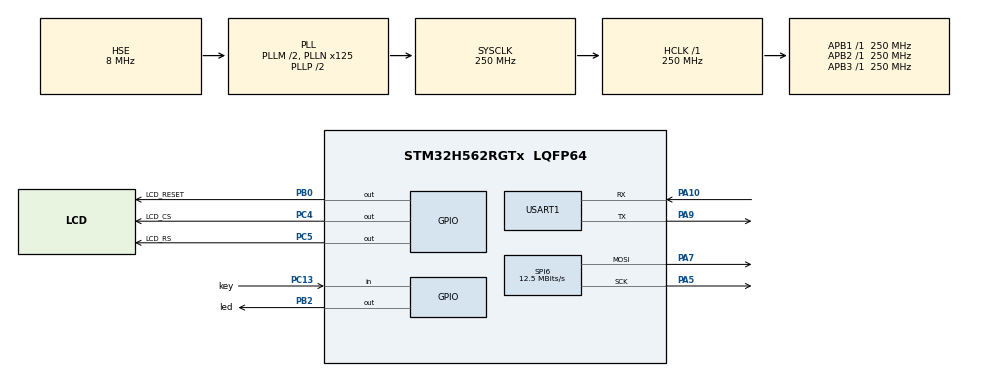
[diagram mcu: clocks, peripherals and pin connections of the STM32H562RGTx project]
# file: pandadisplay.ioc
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BOOTPATH.BootPathName=LEGACY
BOOTPATH.UserSelectedBootPath=LEGACY
CORTEX_M33_NS.userName=CORTEX_M33
Mcu.Family=STM32H5
Mcu.Name=STM32H562RGTx
Mcu.Package=LQFP64
NVIC.PriorityGroup=NVIC_PRIORITYGROUP_4
PA10.Mode=Asynchronous
PA10.Signal=USART1_RX
PA13(JTMS/SWDIO).Mode=Serial_Wire
PA13(JTMS/SWDIO).Signal=DEBUG_JTMS-SWDIO
PA14(JTCK/SWCLK).Mode=Serial_Wire
PA14(JTCK/SWCLK).Signal=DEBUG_JTCK-SWCLK
PA5.Mode=TX_Only_Simplex_Unidirect_Master
PA5.Signal=SPI6_SCK
PA7.Mode=TX_Only_Simplex_Unidirect_Master
PA7.Signal=SPI6_MOSI
PA9.Mode=Asynchronous
PA9.Signal=USART1_TX
PB0.GPIO_Label=LCD_RESET
PB0.PinState=GPIO_PIN_SET
PB0.Signal=GPIO_Output
PB2.GPIO_Label=led
PB2.Signal=GPIO_Output
PC13.GPIO_Label=key
PC13.Signal=GPIO_Input
PC4.GPIO_Label=LCD_CS
PC4.PinState=GPIO_PIN_SET
PC4.Signal=GPIO_Output
PC5.GPIO_Label=LCD_RS
PC5.Signal=GPIO_Output
PH0-OSC_IN(PH0).Mode=HSE-External-Oscillator
PH0-OSC_IN(PH0).Signal=RCC_OSC_IN
PH1-OSC_OUT(PH1).Mode=HSE-External-Oscillator
PH1-OSC_OUT(PH1).Signal=RCC_OSC_OUT
ProjectManager.HeapSize=0x200
ProjectManager.StackSize=0x400
ProjectManager.TargetToolchain=STM32CubeIDE
RCC.ADCFreq_Value=250000000
RCC.AHBFreq_Value=250000000
RCC.APB1Freq_Value=250000000
RCC.APB1TimFreq_Value=250000000
RCC.APB2Freq_Value=250000000
RCC.APB2TimFreq_Value=250000000
RCC.APB3Freq_Value=250000000
RCC.CSI_VALUE=4000000
RCC.CortexFreq_Value=250000000
RCC.EPOD_VALUE=8000000
RCC.HCLKFreq_Value=250000000
RCC.HSE_VALUE=8000000
RCC.HSI48_VALUE=48000000
RCC.HSI_VALUE=64000000
RCC.LSE_VALUE=32768
RCC.LSIRC_VALUE=32000
RCC.PLL2M=2
RCC.PLL2N=125
RCC.PLL2Q=10
RCC.PLL2Source=RCC_PLL2_SOURCE_HSE
RCC.PLLM=2
RCC.PLLN=125
RCC.PLLSourceVirtual=RCC_PLL1_SOURCE_HSE
RCC.SPI6CLockSelection=RCC_SPI6CLKSOURCE_PLL2Q
RCC.SYSCLKFreq_VALUE=250000000
RCC.SYSCLKSource=RCC_SYSCLKSOURCE_PLLCLK
RCC.USBFreq_Value=48000000
RCC.VCOOutputFreq_Value=500000000
SPI6.BaudRatePrescaler=SPI_BAUDRATEPRESCALER_4
SPI6.CLKPhase=SPI_PHASE_1EDGE
SPI6.CLKPolarity=SPI_POLARITY_LOW
SPI6.CalculateBaudRate=12.5 MBits/s
SPI6.DataSize=SPI_DATASIZE_8BIT
SPI6.Direction=SPI_DIRECTION_2LINES_TXONLY
SPI6.IOSwap=SPI_IO_SWAP_DISABLE
SPI6.Mode=SPI_MODE_MASTER
SPI6.VirtualType=VM_MASTER
USART1.VirtualMode-Asynchronous=VM_ASYNC
VP_BOOTPATH_VS_BOOTPATH.Mode=BP_Activate
VP_CORTEX_M33_NS_VS_Hclk.Mode=Hclk_Mode
VP_DCACHE1_VS_DCACHE.Mode=DCACHE_Activate
VP_ICACHE_VS_ICACHE.Mode=DefaultMode
VP_MEMORYMAP_VS_MEMORYMAP.Mode=CurAppReg
VP_PWR_VS_LPOM.Mode=PowerOptimisation
VP_PWR_VS_SECSignals.Mode=Security/Privilege
board=custom

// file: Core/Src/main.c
/* USER CODE BEGIN Header */
/**
  ******************************************************************************
  * @file           : main.c
  * @brief          : Main program body
  ******************************************************************************
  * @attention
  *
  * Copyright (c) 2025 STMicroelectronics.
  * All rights reserved.
  *
  * This software is licensed under terms that can be found in the LICENSE file
  * in the root directory of this software component.
  * If no LICENSE file comes with this software, it is provided AS-IS.
  *
  ******************************************************************************
  */
/* USER CODE END Header */
#include "main.h"

/* USER CODE BEGIN Includes */
#include "st75256.h"
/* USER CODE END Includes */

DCACHE_HandleTypeDef hdcache1;

SPI_HandleTypeDef hspi6;

UART_HandleTypeDef huart1;

void SystemClock_Config(void);
static void MX_GPIO_Init(void);
static void MX_ICACHE_Init(void);
static void MX_USART1_UART_Init(void);
static void MX_DCACHE1_Init(void);
static void MX_SPI6_Init(void);

int main(void)
{

  /* MCU Configuration--------------------------------------------------------*/

  /* Reset of all peripherals, Initializes the Flash interface and the Systick. */
  HAL_Init();

  /* Configure the system clock */
  SystemClock_Config();

  /* Initialize all configured peripherals */
  MX_GPIO_Init();
  MX_ICACHE_Init();
  MX_USART1_UART_Init();
  MX_DCACHE1_Init();
  MX_SPI6_Init();
  /* USER CODE BEGIN 2 */
  lcd_init();

  /* USER CODE END 2 */

  /* Infinite loop */
  /* USER CODE BEGIN WHILE */
  while (1)
  {
	  HAL_GPIO_TogglePin(led_GPIO_Port,led_Pin);

	  HAL_Delay(1000);

	  lcd_active250();
    /* USER CODE END WHILE */

  }
}

void SystemClock_Config(void)
{
  RCC_OscInitTypeDef RCC_OscInitStruct = {0};
  RCC_ClkInitTypeDef RCC_ClkInitStruct = {0};

  /** Configure the main internal regulator output voltage
  */
  __HAL_PWR_VOLTAGESCALING_CONFIG(PWR_REGULATOR_VOLTAGE_SCALE0);

  while(!__HAL_PWR_GET_FLAG(PWR_FLAG_VOSRDY)) {}

  /** Initializes the RCC Oscillators according to the specified parameters
  * in the RCC_OscInitTypeDef structure.
  */
  RCC_OscInitStruct.OscillatorType = RCC_OSCILLATORTYPE_HSE;
  RCC_OscInitStruct.HSEState = RCC_HSE_ON;
  RCC_OscInitStruct.PLL.PLLState = RCC_PLL_ON;
  RCC_OscInitStruct.PLL.PLLSource = RCC_PLL1_SOURCE_HSE;
  RCC_OscInitStruct.PLL.PLLM = 2;
  RCC_OscInitStruct.PLL.PLLN = 125;
  RCC_OscInitStruct.PLL.PLLP = 2;
  RCC_OscInitStruct.PLL.PLLQ = 2;
  RCC_OscInitStruct.PLL.PLLR = 2;
  RCC_OscInitStruct.PLL.PLLRGE = RCC_PLL1_VCIRANGE_2;
  RCC_OscInitStruct.PLL.PLLVCOSEL = RCC_PLL1_VCORANGE_WIDE;
  RCC_OscInitStruct.PLL.PLLFRACN = 0;
  if (HAL_RCC_OscConfig(&RCC_OscInitStruct) != HAL_OK)
  {
    Error_Handler();
  }

  /** Initializes the CPU, AHB and APB buses clocks
  */
  RCC_ClkInitStruct.ClockType = RCC_CLOCKTYPE_HCLK|RCC_CLOCKTYPE_SYSCLK
                              |RCC_CLOCKTYPE_PCLK1|RCC_CLOCKTYPE_PCLK2
                              |RCC_CLOCKTYPE_PCLK3;
  RCC_ClkInitStruct.SYSCLKSource = RCC_SYSCLKSOURCE_PLLCLK;
  RCC_ClkInitStruct.AHBCLKDivider = RCC_SYSCLK_DIV1;
  RCC_ClkInitStruct.APB1CLKDivider = RCC_HCLK_DIV1;
  RCC_ClkInitStruct.APB2CLKDivider = RCC_HCLK_DIV1;
  RCC_ClkInitStruct.APB3CLKDivider = RCC_HCLK_DIV1;

  if (HAL_RCC_ClockConfig(&RCC_ClkInitStruct, FLASH_LATENCY_5) != HAL_OK)
  {
    Error_Handler();
  }

  /** Configure the programming delay
  */
  __HAL_FLASH_SET_PROGRAM_DELAY(FLASH_PROGRAMMING_DELAY_2);
}

static void MX_DCACHE1_Init(void)
{

  hdcache1.Instance = DCACHE1;
  hdcache1.Init.ReadBurstType = DCACHE_READ_BURST_WRAP;
  if (HAL_DCACHE_Init(&hdcache1) != HAL_OK)
  {
    Error_Handler();
  }

}

static void MX_ICACHE_Init(void)
{

  /** Enable instruction cache (default 2-ways set associative cache)
  */
  if (HAL_ICACHE_Enable() != HAL_OK)
  {
    Error_Handler();
  }

}

static void MX_SPI6_Init(void)
{

  /* SPI6 parameter configuration*/
  hspi6.Instance = SPI6;
  hspi6.Init.Mode = SPI_MODE_MASTER;
  hspi6.Init.Direction = SPI_DIRECTION_2LINES_TXONLY;
  hspi6.Init.DataSize = SPI_DATASIZE_8BIT;
  hspi6.Init.CLKPolarity = SPI_POLARITY_LOW;
  hspi6.Init.CLKPhase = SPI_PHASE_1EDGE;
  hspi6.Init.NSS = SPI_NSS_SOFT;
  hspi6.Init.BaudRatePrescaler = SPI_BAUDRATEPRESCALER_4;
  hspi6.Init.FirstBit = SPI_FIRSTBIT_MSB;
  hspi6.Init.TIMode = SPI_TIMODE_DISABLE;
  hspi6.Init.CRCCalculation = SPI_CRCCALCULATION_DISABLE;
  hspi6.Init.CRCPolynomial = 0x7;
  hspi6.Init.NSSPMode = SPI_NSS_PULSE_ENABLE;
  hspi6.Init.NSSPolarity = SPI_NSS_POLARITY_LOW;
  hspi6.Init.FifoThreshold = SPI_FIFO_THRESHOLD_01DATA;
  hspi6.Init.MasterSSIdleness = SPI_MASTER_SS_IDLENESS_00CYCLE;
  hspi6.Init.MasterInterDataIdleness = SPI_MASTER_INTERDATA_IDLENESS_00CYCLE;
  hspi6.Init.MasterReceiverAutoSusp = SPI_MASTER_RX_AUTOSUSP_DISABLE;
  hspi6.Init.MasterKeepIOState = SPI_MASTER_KEEP_IO_STATE_DISABLE;
  hspi6.Init.IOSwap = SPI_IO_SWAP_DISABLE;
  hspi6.Init.ReadyMasterManagement = SPI_RDY_MASTER_MANAGEMENT_INTERNALLY;
  hspi6.Init.ReadyPolarity = SPI_RDY_POLARITY_HIGH;
  if (HAL_SPI_Init(&hspi6) != HAL_OK)
  {
    Error_Handler();
  }

}

static void MX_USART1_UART_Init(void)
{

  huart1.Instance = USART1;
  huart1.Init.BaudRate = 115200;
  huart1.Init.WordLength = UART_WORDLENGTH_8B;
  huart1.Init.StopBits = UART_STOPBITS_1;
  huart1.Init.Parity = UART_PARITY_NONE;
  huart1.Init.Mode = UART_MODE_TX_RX;
  huart1.Init.HwFlowCtl = UART_HWCONTROL_NONE;
  huart1.Init.OverSampling = UART_OVERSAMPLING_16;
  huart1.Init.OneBitSampling = UART_ONE_BIT_SAMPLE_DISABLE;
  huart1.Init.ClockPrescaler = UART_PRESCALER_DIV1;
  huart1.AdvancedInit.AdvFeatureInit = UART_ADVFEATURE_NO_INIT;
  if (HAL_UART_Init(&huart1) != HAL_OK)
  {
    Error_Handler();
  }
  if (HAL_UARTEx_SetTxFifoThreshold(&huart1, UART_TXFIFO_THRESHOLD_1_8) != HAL_OK)
  {
    Error_Handler();
  }
  if (HAL_UARTEx_SetRxFifoThreshold(&huart1, UART_RXFIFO_THRESHOLD_1_8) != HAL_OK)
  {
    Error_Handler();
  }
  if (HAL_UARTEx_DisableFifoMode(&huart1) != HAL_OK)
  {
    Error_Handler();
  }

}

static void MX_GPIO_Init(void)
{
  GPIO_InitTypeDef GPIO_InitStruct = {0};

  /* GPIO Ports Clock Enable */
  __HAL_RCC_GPIOC_CLK_ENABLE();
  __HAL_RCC_GPIOH_CLK_ENABLE();
  __HAL_RCC_GPIOA_CLK_ENABLE();
  __HAL_RCC_GPIOB_CLK_ENABLE();

  /*Configure GPIO pin Output Level */
  HAL_GPIO_WritePin(LCD_CS_GPIO_Port, LCD_CS_Pin, GPIO_PIN_SET);

  /*Configure GPIO pin Output Level */
  HAL_GPIO_WritePin(LCD_RS_GPIO_Port, LCD_RS_Pin, GPIO_PIN_RESET);

  /*Configure GPIO pin Output Level */
  HAL_GPIO_WritePin(LCD_RESET_GPIO_Port, LCD_RESET_Pin, GPIO_PIN_SET);

  /*Configure GPIO pin Output Level */
  HAL_GPIO_WritePin(led_GPIO_Port, led_Pin, GPIO_PIN_RESET);

  /*Configure GPIO pin : key_Pin */
  GPIO_InitStruct.Pin = key_Pin;
  GPIO_InitStruct.Mode = GPIO_MODE_INPUT;
  GPIO_InitStruct.Pull = GPIO_NOPULL;
  HAL_GPIO_Init(key_GPIO_Port, &GPIO_InitStruct);

  /*Configure GPIO pins : LCD_CS_Pin LCD_RS_Pin */
  GPIO_InitStruct.Pin = LCD_CS_Pin|LCD_RS_Pin;
  GPIO_InitStruct.Mode = GPIO_MODE_OUTPUT_PP;
  GPIO_InitStruct.Pull = GPIO_NOPULL;
  GPIO_InitStruct.Speed = GPIO_SPEED_FREQ_LOW;
  HAL_GPIO_Init(GPIOC, &GPIO_InitStruct);

  /*Configure GPIO pins : LCD_RESET_Pin led_Pin */
  GPIO_InitStruct.Pin = LCD_RESET_Pin|led_Pin;
  GPIO_InitStruct.Mode = GPIO_MODE_OUTPUT_PP;
  GPIO_InitStruct.Pull = GPIO_NOPULL;
  GPIO_InitStruct.Speed = GPIO_SPEED_FREQ_LOW;
  HAL_GPIO_Init(GPIOB, &GPIO_InitStruct);

}

void Error_Handler(void)
{
  __disable_irq();
  while (1)
  {
  }
}
